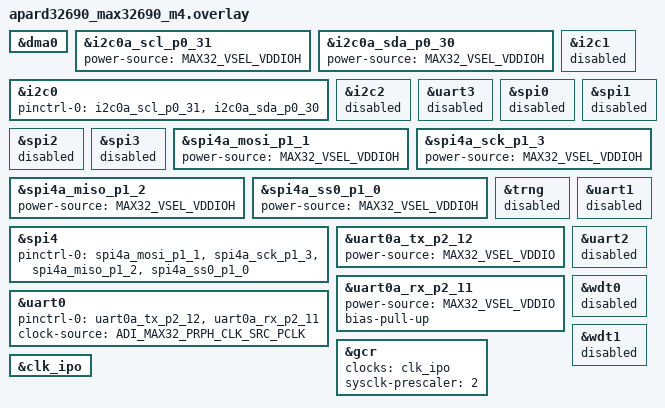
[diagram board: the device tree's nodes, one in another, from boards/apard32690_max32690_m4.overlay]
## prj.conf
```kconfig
CONFIG_GPIO=y

# Enable thread awareness for debug
CONFIG_THREAD_NAME=y
CONFIG_DEBUG_THREAD_INFO=y
CONFIG_THREAD_ANALYZER=y

# Enable these configs for our
CONFIG_LOG=y
CONFIG_SHELL=y
CONFIG_SENSOR=y
CONFIG_SENSOR_INFO=y
CONFIG_SENSOR_SHELL=y
CONFIG_SENSOR_LOG_LEVEL_DBG=y
```

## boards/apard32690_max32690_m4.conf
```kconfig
 # Configuration for MAX32690-WLP
 #
 # This file was automatically generated using Analog Devices Config
 # https://github.com/adi-ctx/cfs-cfsutil
 #
 # Generated at: 2024-10-16T18:13:17.294Z
 # Generated with: C:\analog\cfs\1.0.0\Utils\cfsutil\bin\node.exe C:\analog\cfs\1.0.0\Utils\cfsutil\bin\run generate --engine zephyr --input c:\workspace\cfs_projects\EWNA_REPO\Zephyr_PmodACL\m4\max32690-wlp.cfsconfig --preview --format json
 #
 # SPDX-License-Identifier: Apache-2.0
 # Copyright (c) 2024 Analog Devices, Inc.

CONFIG_I2C=y
CONFIG_SERIAL=y
CONFIG_SPI=y
```

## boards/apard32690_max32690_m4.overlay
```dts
/**
 * Configuration for MAX32690-WLP
 *
 * This file was automatically generated using Analog Devices Config
 * https://github.com/adi-ctx/cfs-cfsutil
 *
 * Generated at: 2024-10-16T18:13:17.276Z
 * Generated with: C:\analog\cfs\1.0.0\Utils\cfsutil\bin\node.exe C:\analog\cfs\1.0.0\Utils\cfsutil\bin\run generate --engine zephyr --input c:\workspace\cfs_projects\EWNA_REPO\Zephyr_PmodACL\m4\max32690-wlp.cfsconfig --preview --format json
 *
 * SPDX-License-Identifier: Apache-2.0
 * Copyright (c) 2024 Analog Devices, Inc.
 */


/* GPIO Configuration */

/* No GPIO signals to configure. */

/* Peripheral Configuration */

&dma0 {
	status = "okay";
};

&i2c0a_scl_p0_31 {
	power-source = <MAX32_VSEL_VDDIOH>;
};

&i2c0a_sda_p0_30 {
	power-source = <MAX32_VSEL_VDDIOH>;
};

&i2c0 {
	pinctrl-0 = <&i2c0a_scl_p0_31 &i2c0a_sda_p0_30>;
	pinctrl-names = "default";
	status = "okay";
};

&i2c1 {
	status = "disabled";
};

&i2c2 {
	status = "disabled";
};

&uart3 {
	status = "disabled";
};

&spi0 {
	status = "disabled";
};

&spi1 {
	status = "disabled";
};

&spi2 {
	status = "disabled";
};

&spi3 {
	status = "disabled";
};

&spi4a_mosi_p1_1 {
	power-source = <MAX32_VSEL_VDDIOH>;
};

&spi4a_sck_p1_3 {
	power-source = <MAX32_VSEL_VDDIOH>;
};

&spi4a_miso_p1_2 {
	power-source = <MAX32_VSEL_VDDIOH>;
};

&spi4a_ss0_p1_0 {
	power-source = <MAX32_VSEL_VDDIOH>;
};

&spi4 {
	pinctrl-0 = <&spi4a_mosi_p1_1 &spi4a_sck_p1_3 &spi4a_miso_p1_2 &spi4a_ss0_p1_0>;
	pinctrl-names = "default";
	status = "okay";
};

&trng {
	status = "disabled";
};

&uart0a_tx_p2_12 {
	power-source = <MAX32_VSEL_VDDIO>;
};

&uart0a_rx_p2_11 {
	power-source = <MAX32_VSEL_VDDIO>;
	/* Weak pull-up is not supported here in Zephyr. Using strong pull-up instead. */
	bias-pull-up;
};

&uart0 {
	pinctrl-0 = <&uart0a_tx_p2_12 &uart0a_rx_p2_11>;
	pinctrl-names = "default";
	status = "okay";
	clock-source = <ADI_MAX32_PRPH_CLK_SRC_PCLK>;
};

&uart1 {
	status = "disabled";
};

&uart2 {
	status = "disabled";
};

&wdt0 {
	status = "disabled";
};

&wdt1 {
	status = "disabled";
};


/* Clock Configuration and Initialization */

/* System clock configuration */
&gcr {
	clocks = <&clk_ipo>;
	sysclk-prescaler = <2>;
};

&clk_ipo {
	status = "okay";
};
```

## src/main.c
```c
/*
 * Copyright (c) 2016 Intel Corporation
 *
 * SPDX-License-Identifier: Apache-2.0
 */

#include <stdio.h>
#include <zephyr/kernel.h>
#include <zephyr/drivers/gpio.h>

/* 1000 msec = 1 sec */
#define SLEEP_TIME_MS   1000

/* The devicetree node identifier for the "led0" alias. */
#define LED0_NODE DT_ALIAS(led0)

/*
 * A build error on this line means your board is unsupported.
 * See the sample documentation for information on how to fix this.
 */
static const struct gpio_dt_spec led = GPIO_DT_SPEC_GET(LED0_NODE, gpios);

int main(void)
{
	int ret;
	bool led_state = true;

	if (!gpio_is_ready_dt(&led)) {
		return 0;
	}

	ret = gpio_pin_configure_dt(&led, GPIO_OUTPUT_ACTIVE);
	if (ret < 0) {
		return 0;
	}

	while (1) {
		ret = gpio_pin_toggle_dt(&led);
		if (ret < 0) {
			return 0;
		}

		led_state = !led_state;
		/** NOTE: Commented out to avoid mixing with sensor shell output */
		// printf("LED state: %s\n", led_state ? "ON" : "OFF");
		k_msleep(SLEEP_TIME_MS);
	}
	return 0;
}
```
